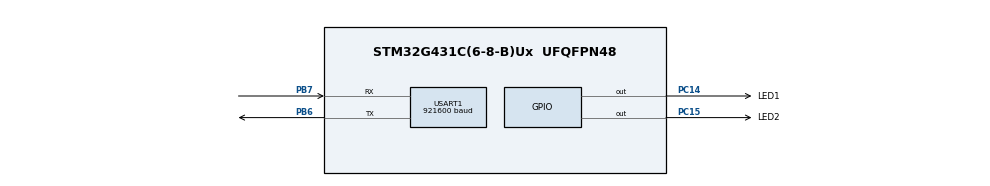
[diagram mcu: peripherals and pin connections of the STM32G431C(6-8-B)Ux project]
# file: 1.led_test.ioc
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Dma.Request0=USART1_TX
Dma.USART1_TX.0.Direction=DMA_MEMORY_TO_PERIPH
Dma.USART1_TX.0.EventEnable=DISABLE
Dma.USART1_TX.0.Instance=DMA1_Channel1
Dma.USART1_TX.0.MemDataAlignment=DMA_MDATAALIGN_BYTE
Dma.USART1_TX.0.MemInc=DMA_MINC_ENABLE
Dma.USART1_TX.0.Mode=DMA_NORMAL
Dma.USART1_TX.0.PeriphDataAlignment=DMA_PDATAALIGN_BYTE
Dma.USART1_TX.0.PeriphInc=DMA_PINC_DISABLE
Dma.USART1_TX.0.Polarity=HAL_DMAMUX_REQ_GEN_RISING
Dma.USART1_TX.0.Priority=DMA_PRIORITY_LOW
Dma.USART1_TX.0.RequestNumber=1
Dma.USART1_TX.0.SignalID=NONE
Dma.USART1_TX.0.SyncEnable=DISABLE
Dma.USART1_TX.0.SyncPolarity=HAL_DMAMUX_SYNC_NO_EVENT
Dma.USART1_TX.0.SyncRequestNumber=1
Dma.USART1_TX.0.SyncSignalID=NONE
Mcu.Family=STM32G4
Mcu.Name=STM32G431C(6-8-B)Ux
Mcu.Package=UFQFPN48
NVIC.DMA1_Channel1_IRQn=true\:0\:0\:false\:false\:true\:false\:true\:true
NVIC.PriorityGroup=NVIC_PRIORITYGROUP_4
NVIC.USART1_IRQn=true\:0\:0\:false\:false\:true\:true\:true\:true
PA13.Mode=Serial_Wire
PA13.Signal=SYS_JTMS-SWDIO
PA14.Mode=Serial_Wire
PA14.Signal=SYS_JTCK-SWCLK
PB6.Mode=Asynchronous
PB6.Signal=USART1_TX
PB7.Mode=Asynchronous
PB7.Signal=USART1_RX
PC14-OSC32_IN.GPIO_Label=LED1
PC14-OSC32_IN.PinState=GPIO_PIN_SET
PC14-OSC32_IN.Signal=GPIO_Output
PC15-OSC32_OUT.GPIO_Label=LED2
PC15-OSC32_OUT.PinState=GPIO_PIN_SET
PC15-OSC32_OUT.Signal=GPIO_Output
PF0-OSC_IN.Mode=HSE-External-Oscillator
PF0-OSC_IN.Signal=RCC_OSC_IN
PF1-OSC_OUT.Mode=HSE-External-Oscillator
PF1-OSC_OUT.Signal=RCC_OSC_OUT
ProjectManager.HeapSize=0x200
ProjectManager.StackSize=0x400
ProjectManager.TargetToolchain=MDK-ARM V5.32
RCC.ADC12Freq_Value=170000000
RCC.AHBFreq_Value=170000000
RCC.APB1Freq_Value=170000000
RCC.APB1TimFreq_Value=170000000
RCC.APB2Freq_Value=170000000
RCC.APB2TimFreq_Value=170000000
RCC.CortexFreq_Value=170000000
RCC.EXTERNAL_CLOCK_VALUE=12288000
RCC.HCLKFreq_Value=170000000
RCC.HSE_VALUE=24000000
RCC.HSI48_VALUE=48000000
RCC.HSI_VALUE=16000000
RCC.LSE_VALUE=32768
RCC.PLLM=RCC_PLLM_DIV6
RCC.PLLN=85
RCC.PLLSourceVirtual=RCC_PLLSOURCE_HSE
RCC.SYSCLKFreq_VALUE=170000000
RCC.SYSCLKSource=RCC_SYSCLKSOURCE_PLLCLK
RCC.USBFreq_Value=170000000
RCC.VCOOutputFreq_Value=340000000
USART1.BaudRate=921600
USART1.VirtualMode-Asynchronous=VM_ASYNC
VP_SYS_VS_DBSignals.Mode=DisableDeadBatterySignals
board=custom

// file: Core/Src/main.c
/* USER CODE BEGIN Header */
/**
 ******************************************************************************
 * @file           : main.c
 * @brief          : Main program body
 ******************************************************************************
 * @attention
 *
 * Copyright (c) 2024 STMicroelectronics.
 * All rights reserved.
 *
 * This software is licensed under terms that can be found in the LICENSE file
 * in the root directory of this software component.
 * If no LICENSE file comes with this software, it is provided AS-IS.
 *
 ******************************************************************************
 */
/* USER CODE END Header */
#include "main.h"
#include "dma.h"
#include "usart.h"
#include "gpio.h"

/* USER CODE BEGIN Includes */
#include "Serial.h"
/* USER CODE END Includes */

void SystemClock_Config(void);

int main(void)
{

  /* MCU Configuration--------------------------------------------------------*/

  /* Reset of all peripherals, Initializes the Flash interface and the Systick. */
  LL_APB2_GRP1_EnableClock(LL_APB2_GRP1_PERIPH_SYSCFG);
  LL_APB1_GRP1_EnableClock(LL_APB1_GRP1_PERIPH_PWR);

  /* System interrupt init*/
  NVIC_SetPriorityGrouping(NVIC_PRIORITYGROUP_4);

  /* SysTick_IRQn interrupt configuration */
  NVIC_SetPriority(SysTick_IRQn, NVIC_EncodePriority(NVIC_GetPriorityGrouping(), 15, 0));

  /** Disable the internal Pull-Up in Dead Battery pins of UCPD peripheral
   */
  LL_PWR_DisableUCPDDeadBattery();

  /* Configure the system clock */
  SystemClock_Config();

  /* Initialize all configured peripherals */
  MX_GPIO_Init();
  MX_DMA_Init();
  MX_USART1_UART_Init();
  /* USER CODE BEGIN 2 */
  debug_init();
  /* USER CODE END 2 */

  /* Infinite loop */
  /* USER CODE BEGIN WHILE */
  while (1)
  {
    log_DMA_TX("LL DMA test\r\n");
    // log_block_TX("stm32 ll\r\n");

    /* USER CODE END WHILE */

  }
}

void SystemClock_Config(void)
{
  LL_FLASH_SetLatency(LL_FLASH_LATENCY_4);
  while (LL_FLASH_GetLatency() != LL_FLASH_LATENCY_4)
  {
  }
  LL_PWR_EnableRange1BoostMode();
  LL_RCC_HSE_Enable();
  /* Wait till HSE is ready */
  while (LL_RCC_HSE_IsReady() != 1)
  {
  }

  LL_RCC_PLL_ConfigDomain_SYS(LL_RCC_PLLSOURCE_HSE, LL_RCC_PLLM_DIV_6, 85, LL_RCC_PLLR_DIV_2);
  LL_RCC_PLL_EnableDomain_SYS();
  LL_RCC_PLL_Enable();
  /* Wait till PLL is ready */
  while (LL_RCC_PLL_IsReady() != 1)
  {
  }

  LL_RCC_SetSysClkSource(LL_RCC_SYS_CLKSOURCE_PLL);
  LL_RCC_SetAHBPrescaler(LL_RCC_SYSCLK_DIV_2);
  /* Wait till System clock is ready */
  while (LL_RCC_GetSysClkSource() != LL_RCC_SYS_CLKSOURCE_STATUS_PLL)
  {
  }

  /* Insure 1us transition state at intermediate medium speed clock*/
  for (__IO uint32_t i = (170 >> 1); i != 0; i--)
    ;

  /* Set AHB prescaler*/
  LL_RCC_SetAHBPrescaler(LL_RCC_SYSCLK_DIV_1);
  LL_RCC_SetAPB1Prescaler(LL_RCC_APB1_DIV_1);
  LL_RCC_SetAPB2Prescaler(LL_RCC_APB2_DIV_1);

  LL_Init1msTick(170000000);

  LL_SetSystemCoreClock(170000000);
}

void Error_Handler(void)
{
  __disable_irq();
  while (1)
  {
  }
}
